# TREMO register map
File version: 1.6.2
CPU: CM4 r0p1, little endian, MPU, FPU, 3 interrupt priority bits
Registers are 32-bit, read-write, reset 0x0 unless marked. A register's access mark holds for its fields unless they carry their own. Offsets are from the block's base; [hi:lo] are bit positions; {n}, {i} and the like mark numbered series; 'fields as' and 'values as' point back to an identical list.

## DMAC0 — DMA
Base 0x40023000
Same registers: DMAC1 0x40024000
{0x0+0x58*i} SAR{i} 64-bit (i=0..3) — source address register
  [31:0] SAR — source address
{0x8+0x58*i} DAR{i} 64-bit (i=0..3) — destination address register
  [31:0] DAR — destination address
{0x10+0x58*i} LLP{i} 64-bit (i=0..3) — linked list pointer register
  [31:0] LOC — first address of the LLI linked list
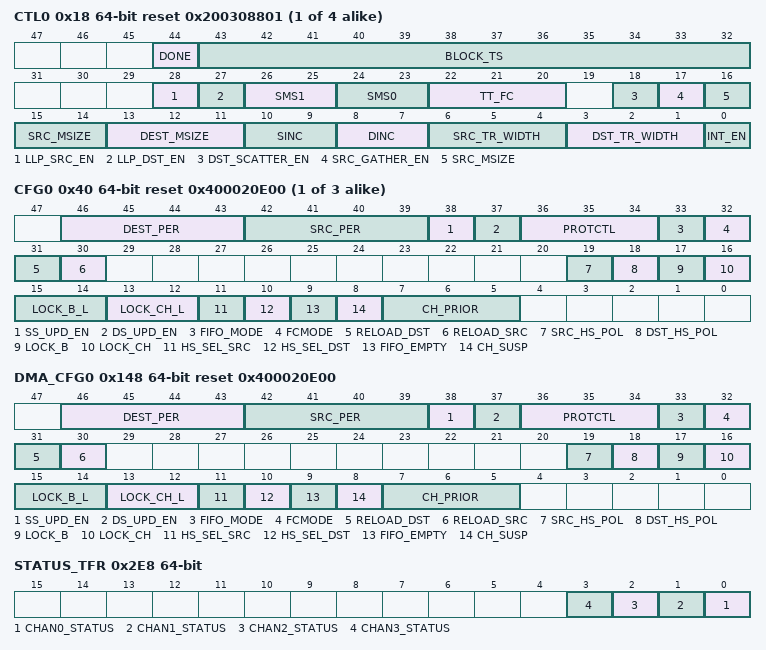
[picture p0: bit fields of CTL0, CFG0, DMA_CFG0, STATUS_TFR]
{0x18+0x58*i} CTL{i} 64-bit reset 0x200308801 (i=0..3) — channel control register
  [44] DONE — block in the LLI linked list has been transferred
  [43:32] BLOCK_TS — length of block
  [28] LLP_SRC_EN — DMA source enable LLI linked list
  [27] LLP_DST_EN — DMA destination enable LLI linked list
  [26:25] SMS1 — AHB master selection for DMA source
  [24:23] SMS0 — AHB master selection for DMA purposes
  [22:20] TT_FC — DMA data movement method
  [18] DST_SCATTER_EN — destination enable scatter
  [17] SRC_GATHER_EN — DMA source enable gather
  [16:14] SRC_MSIZE — source burst length
  [13:11] DEST_MSIZE — destination burst length
  [10:9] SINC — DMA source address control
  [8:7] DINC — DMA destination address control
  [6:4] SRC_TR_WIDTH — DMA source data width
  [3:1] DST_TR_WIDTH — DMA destination data width
  [0] INT_EN — DMA interrupt enable
{0x40+0x58*i} CFG{i} 64-bit reset 0x400020E00 (i=0..2) — channel configuration register
  [46:43] DEST_PER — DMA destination handshake interface
  [42:39] SRC_PER — DMA source handshake interface
  [38] SS_UPD_EN — DMA source status update enable
  [37] DS_UPD_EN — DMA destination status update enable
  [36:34] PROTCTL — protection control
  [33] FIFO_MODE — FIFO mode selection
  [32] FCMODE — Source flow control mode selection
  [31] RELOAD_DST — DMA destination auto-reloading enable
  [30] RELOAD_SRC — DMA source auto-reloading enable
  [19] SRC_HS_POL — DMA source handshake interface message Polarity
  [18] DST_HS_POL — DMA destination handshake interface message polarity
  [17] LOCK_B — bus lock control
  [16] LOCK_CH — DMA channel lock control
  [15:14] LOCK_B_L — bus lock delay
  [13:12] LOCK_CH_L — DMA channel lock delay
  [11] HS_SEL_SRC — DMA source handshake signal selection
  [10] HS_SEL_DST — DMA destination handshake signal selection
  [9] FIFO_EMPTY
  [8] CH_SUSP — suspend DMA channel FIFO
  [7:5] CH_PRIOR — DMA channel priority
0x148 DMA_CFG0 64-bit reset 0x400020E00 — channel configuration register
  fields as CFG0
0x2E8 STATUS_TFR 64-bit ro — DMA transfer complete interrupt status register
  [n] CHAN{n}_STATUS (n=0..3) — DMA channel {n} transfer completion status
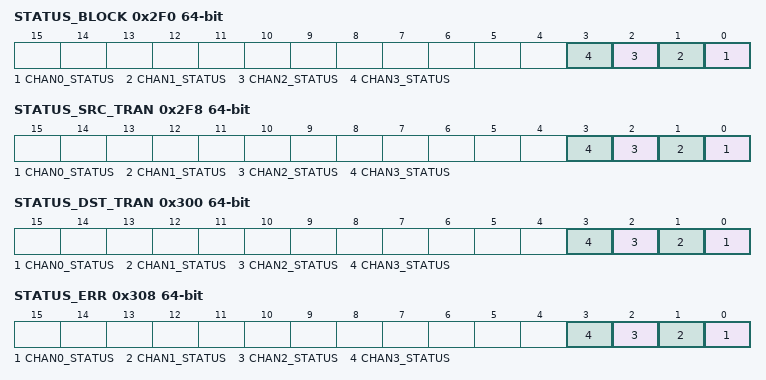
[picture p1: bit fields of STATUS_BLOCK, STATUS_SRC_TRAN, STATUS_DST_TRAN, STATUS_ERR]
0x2F0 STATUS_BLOCK 64-bit ro — DMA block transfer complete interrupt status register
  [n] CHAN{n}_STATUS (n=0..3) — DMA channel {n} block transfer completion status
0x2F8 STATUS_SRC_TRAN 64-bit ro — DMA source processing completed interrupt status register
  [n] CHAN{n}_STATUS (n=0..3) — Source transfer completion status of DMA channel {n}
0x300 STATUS_DST_TRAN 64-bit ro — DMA source processing completed interrupt status register
  [n] CHAN{n}_STATUS (n=0..3) — Destination transfer completion status of DMA channel {n}
0x308 STATUS_ERR 64-bit ro — DMA transmission error status register
  [n] CHAN{n}_STATUS (n=0..3) — channel {n} transmission error status
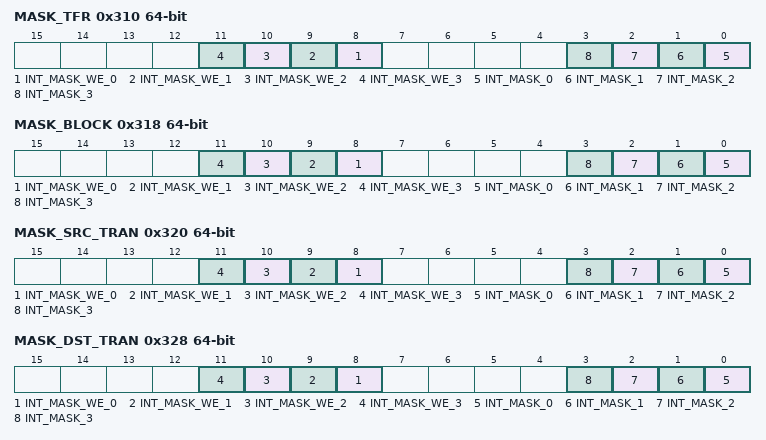
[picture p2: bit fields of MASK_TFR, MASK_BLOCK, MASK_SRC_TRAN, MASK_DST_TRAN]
0x310 MASK_TFR 64-bit — DMA transfer complete interrupt enable register
  [n+8] INT_MASK_WE_{n} wo (n=0..3) — DMA channel{n} transfer completion interrupt mask write enable
  [n] INT_MASK_{n} (n=0..3) — DMA channel{n} transfer completion interrupt enable
0x318 MASK_BLOCK 64-bit — DMA block transfer complete interrupt enable register
  fields as MASK_TFR
0x320 MASK_SRC_TRAN 64-bit — DMA source block transfer complete interrupt enable register
  [n+8] INT_MASK_WE_{n} wo (n=0..3) — DMA channel{n} source transfer complete interrupt mask write enable
  [n] INT_MASK_{n} (n=0..3) — source transfer completion channel{n} interrupt enable
0x328 MASK_DST_TRAN 64-bit — DMA destination block transfer complete interrupt enable register
  [n+8] INT_MASK_WE_{n} wo (n=0..3) — DMA channel{n} destination transfer complete interrupt mask write enable
  [n] INT_MASK_{n} (n=0..3) — destination transfer completion channel{n} interrupt enable
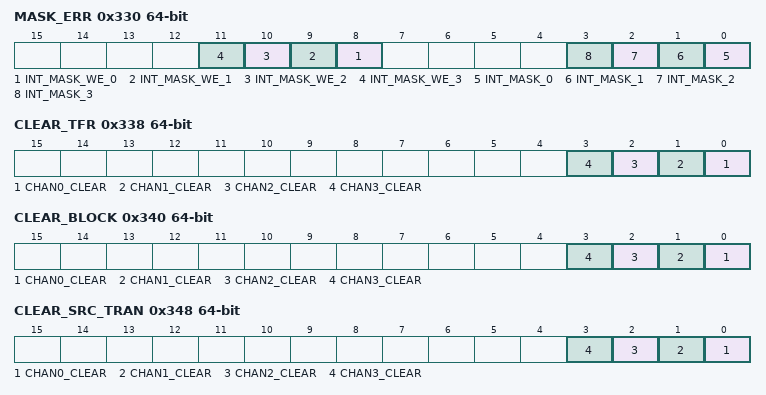
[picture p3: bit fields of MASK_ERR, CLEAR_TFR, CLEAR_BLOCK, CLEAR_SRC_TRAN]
0x330 MASK_ERR 64-bit — DMA transmission error interrupt enable register
  [n+8] INT_MASK_WE_{n} wo (n=0..3) — DMA channel{n} transmission error interrupt mask write enable
  [n] INT_MASK_{n} (n=0..3) — destination transmission error channel{n} interrupt enable
0x338 CLEAR_TFR 64-bit wo — DMA transfer completion status clear register
  [n] CHAN{n}_CLEAR (n=0..3) — clear DMA channel{n} transfer completion status
0x340 CLEAR_BLOCK 64-bit wo — DMA block transfer completion status clear register
  [n] CHAN{n}_CLEAR (n=0..3) — clear DMA channel{n} block transfer completion status
0x348 CLEAR_SRC_TRAN 64-bit wo — DMA source transfer completion status clear register
  [n] CHAN{n}_CLEAR (n=0..3) — clear DMA channel{n} source transfer completion status
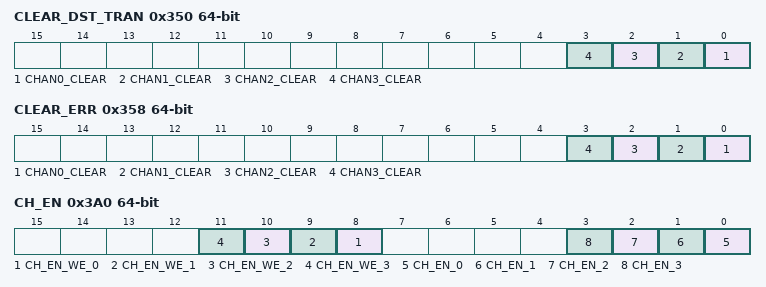
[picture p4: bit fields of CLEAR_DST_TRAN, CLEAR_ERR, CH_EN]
0x350 CLEAR_DST_TRAN 64-bit wo — DMA destination transfer completion status clear register
  [n] CHAN{n}_CLEAR (n=0..3) — clear DMA channel{n} destination transfer completion status
0x358 CLEAR_ERR 64-bit wo — DMA transfer error status clear register
  [n] CHAN{n}_CLEAR (n=0..3) — clear DMA channel{n} transfer error status
0x398 CFG 64-bit — DMA enable control register
  [0] DMA_EN — DMA enable
0x3A0 CH_EN 64-bit — DMA transfer complete interrupt enable register
  [n+8] CH_EN_WE_{n} wo (n=0..3) — DMA channel{n} enable control write enable
  [n] CH_EN_{n} (n=0..3) — DMA channel{n} enable
